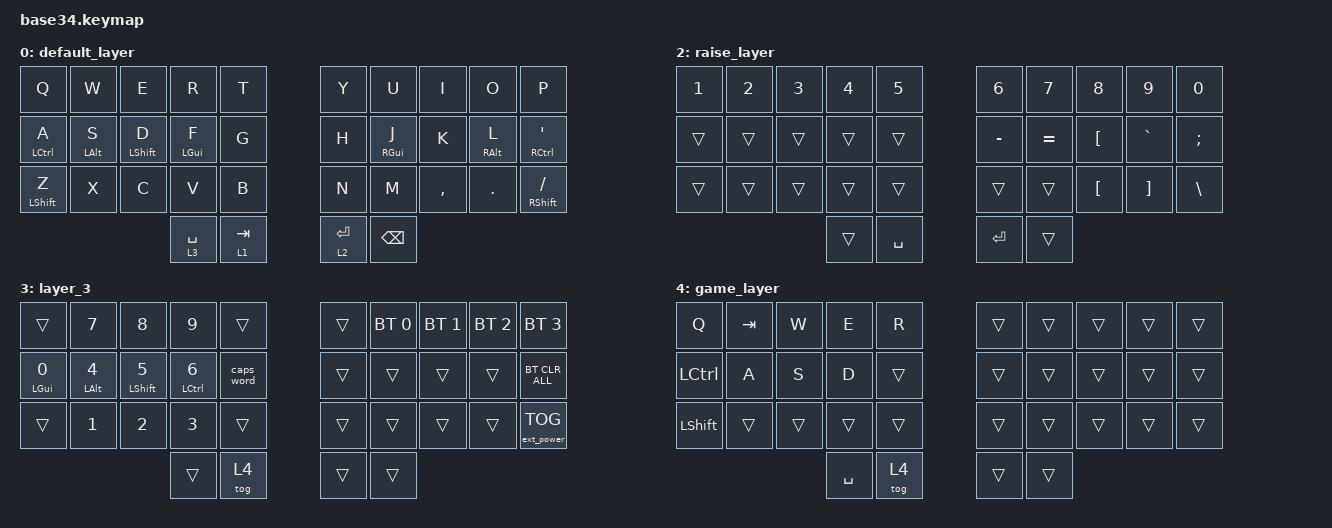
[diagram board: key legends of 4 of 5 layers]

#include <behaviors.dtsi>
#include <dt-bindings/zmk/keys.h>
#include <dt-bindings/zmk/bt.h>
#include <dt-bindings/zmk/outputs.h>
#include <dt-bindings/zmk/ext_power.h>


/* Combos */
/ {
    combos {
        compatible = "zmk,combos";
        combo_game {
            // TAB-thumb + BACKSPACE-thumb (one per thumb): squeeze together to toggle gaming mode.
            // SPACE stays out of it so it's just space.
            timeout-ms = <125>;
            key-positions = <31 33>;
            bindings = <&tog 4>;
            layers = <0 4>;
        };
    };
};

/* Keymap */
/ {
    behaviors {
        hm: homerow_mods {
            compatible = "zmk,behavior-hold-tap";
            #binding-cells = <2>;
            tapping-term-ms = <150>;
            quick-tap-ms = <0>;
            flavor = "tap-preferred";
            bindings = <&kp>, <&kp>;
        };
    };

    keymap {
        compatible = "zmk,keymap";

        default_layer {
           bindings = <           
// ╭─────────────┬─────────────┬─────────────┬─────────────┬─────────────╮  ╭─────────────┬─────────────┬─────────────┬─────────────┬─────────────╮ ╭──────╮
      &kp Q         &kp W         &kp E         &kp R         &kp T             &kp Y         &kp U         &kp I         &kp O         &kp P        
// ├─────────────┼─────────────┼─────────────┼─────────────┼─────────────┤  ├─────────────┼─────────────┼─────────────┼─────────────┼─────────────┤ ├──────┤
      &hm LCTRL A  &hm LALT S   &hm LSHFT D  &hm LEFT_GUI F   &kp G             &kp H         &hm RIGHT_GUI J  &kp K      &hm RIGHT_ALT L &hm RIGHT_CONTROL SINGLE_QUOTE
// ├─────────────┼─────────────┼─────────────┼─────────────┼─────────────┤  ├─────────────┼─────────────┼─────────────┼─────────────┼─────────────┤ ├──────┤
      &mt LSHFT Z   &kp X         &kp C         &kp V         &kp B             &kp N         &kp M         &kp COMMA  &kp DOT    &mt RSHFT FSLH  
// ╰─────────────┼─────────────┴─────────────┼─────────────┼─────────────┤  ├─────────────┼─────────────┼─────────────┴───────────────────────────╯ ├──────┤
                                                &lt 3 SPACE   &lt 1 TAB         &lt 2 RET     &kp BACKSPACE                                          
//                                           ╰─────────────┴─────────────╯  ╰─────────────┴─────────────╯                                           ╰──────╯
           >;
        };

        lower_layer {
            bindings = <            
// ╭─────────────┬─────────────┬─────────────┬─────────────┬─────────────╮ ╭─────────────┬─────────────┬─────────────┬─────────────┬─────────────╮ ╭──────╮
       &kp N1           &kp N2      &kp N3         &kp N4         &kp N5         &kp N6        &kp N7        &kp UP_ARROW  &kp N9        &kp N0         
// ├─────────────┼─────────────┼─────────────┼─────────────┼─────────────┤ ├─────────────┼─────────────┼─────────────┼─────────────┼─────────────┤ ├──────┤
       &kp F1           &kp F2      &kp F3         &kp F4         &kp F5         &kp F6        &kp LEFT      &kp DOWN      &kp RIGHT     &kp DELETE     
// ├─────────────┼─────────────┼─────────────┼─────────────┼─────────────┤ ├─────────────┼─────────────┼─────────────┼─────────────┼─────────────┤ ├──────┤
       &kp F7           &kp F8      &kp F9         &kp F10        &kp F11        &kp F12         &trans          &trans           &trans           &kp ESC 
// ╰─────────────┼─────────────┴─────────────┼─────────────┼─────────────┤ ├─────────────┼─────────────┼─────────────┴───────────────────────────╯ ├──────┤
                                                 &trans           &trans    &none     &trans             &trans                                      
//                                           ╰─────────────┴─────────────╯ ╰─────────────┴─────────────╯                                           ╰──────╯
            >;
        };

        raise_layer {
            bindings =  <            
// ╭─────────────┬─────────────┬─────────────┬─────────────┬─────────────╮  ╭─────────────┬─────────────┬─────────────┬─────────────┬─────────────╮ ╭──────╮
       &kp NUMBER_1  &kp NUMBER_2  &kp NUMBER_3  &kp NUMBER_4  &kp NUMBER_5     &kp NUMBER_6  &kp NUMBER_7  &kp NUMBER_8  &kp NUMBER_9  &kp NUMBER_0    
// ├─────────────┼─────────────┼─────────────┼─────────────┼─────────────┤  ├─────────────┼─────────────┼─────────────┼─────────────┼─────────────┤ ├──────┤
       &trans       &trans       &trans          &trans       &trans          &kp MINUS     &kp EQUAL     &kp LBKT      &kp GRAVE     &kp SEMICOLON   
// ├─────────────┼─────────────┼─────────────┼─────────────┼─────────────┤  ├─────────────┼─────────────┼─────────────┼─────────────┼─────────────┤ ├──────┤
       &trans       &trans       &trans          &trans       &trans         &trans         &trans      &kp LEFT_BRACKET &kp RIGHT_BRACKET  &kp BACKSLASH      
// ╰─────────────┼─────────────┴─────────────┼─────────────┼─────────────┤  ├─────────────┼─────────────┼─────────────┴───────────────────────────╯ ├──────┤
                                                 &trans         &kp SPACE     &kp RET       &trans                                                     
//                                           ╰─────────────┴─────────────╯  ╰─────────────┴─────────────╯                                           ╰──────╯
            >;
        };

        layer_3 {
            bindings = <            
// ╭─────────────┬─────────────┬─────────────┬─────────────┬─────────────╮  ╭─────────────┬─────────────┬─────────────┬─────────────┬─────────────╮ ╭──────╮
       &trans           &kp N7        &kp N8        &kp N9        &trans       &trans           &bt BT_SEL 0  &bt BT_SEL 1  &bt BT_SEL 2  &bt BT_SEL 3 
// ├─────────────┼─────────────┼─────────────┼─────────────┼─────────────┤  ├─────────────┼─────────────┼─────────────┼─────────────┼─────────────┤ ├──────┤
       &hm LGUI N0  &hm LALT N4  &hm LSHFT N5 &hm LCTRL N6  &caps_word         &trans           &trans           &trans    &trans      &bt BT_CLR_ALL  
// ├─────────────┼─────────────┼─────────────┼─────────────┼─────────────┤  ├─────────────┼─────────────┼─────────────┼─────────────┼─────────────┤ ├──────┤
       &trans           &kp N1        &kp N2        &kp N3        &trans       &trans           &trans      &trans     &trans        &ext_power EP_TOG 
// ╰─────────────┼─────────────┴─────────────┼─────────────┼─────────────┤  ├─────────────┼─────────────┼─────────────┴───────────────────────────╯ ├──────┤
                                                 &trans           &tog 4       &trans           &trans                                                  
//                                           ╰─────────────┴─────────────╯  ╰─────────────┴─────────────╯                                           ╰──────╯
            >;
        };

        game_layer {
            // Gaming mode: Q TAB W E R on top row (no outer key for TAB on 34-key),
            // A S D plain on the home row, LCTRL on the corner, plain LSHIFT on the Z-spot.
            // All plain keys (no hold-taps). SPACE is just space.
            // Enter/Exit: squeeze TAB-thumb + BACKSPACE-thumb together.
            bindings = <
// ╭─────────────┬─────────────┬─────────────┬─────────────┬─────────────╮  ╭─────────────┬─────────────┬─────────────┬─────────────┬─────────────╮ ╭──────╮
      &kp Q              &kp TAB      &kp W         &kp E           &kp R           &trans        &trans        &trans        &trans        &trans
// ├─────────────┼─────────────┼─────────────┼─────────────┼─────────────┤  ├─────────────┼─────────────┼─────────────┼─────────────┼─────────────┤ ├──────┤
      &kp LCTRL      &kp A         &kp S         &kp D         &trans        &trans        &trans        &trans        &trans        &trans
// ├─────────────┼─────────────┼─────────────┼─────────────┼─────────────┤  ├─────────────┼─────────────┼─────────────┼─────────────┼─────────────┤ ├──────┤
      &kp LSHIFT       &trans        &trans        &trans        &trans        &trans        &trans        &trans        &trans        &trans
// ╰─────────────┼─────────────┴─────────────┼─────────────┼─────────────┤  ├─────────────┼─────────────┼─────────────┴───────────────────────────╯ ├──────┤
                                                 &kp SPACE      &tog 4       &trans        &trans
//                                           ╰─────────────┴─────────────╯  ╰─────────────┴─────────────╯                                           ╰──────╯
            >;
        };
    };

};
